# PY32F002Bxx register map
Vendor: Puya; Series: PY32F0; File version: 1.0.0
CPU: CM0+ r0p1, little endian, no MPU, no FPU, 4 interrupt priority bits
Registers are 32-bit, read-write, reset 0x0 unless marked. A register's access mark holds for its fields unless they carry their own. Offsets are from the block's base; [hi:lo] are bit positions; 'fields as' and 'values as' point back to an identical list.

## RCC — Reset and clock control
Base 0x40021000
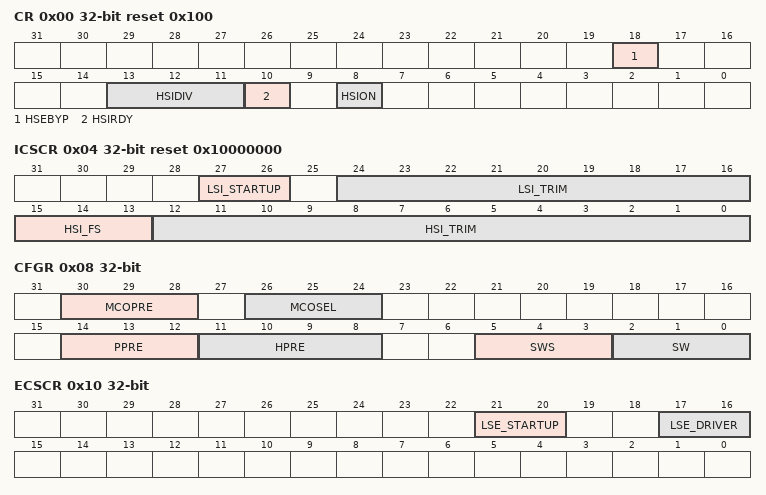
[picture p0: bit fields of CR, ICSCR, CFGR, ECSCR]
0x00 CR reset 0x100 — Clock control register
  [18] HSEBYP
    0=NotBypassed (HSE oscillator not bypassed); 1=Bypassed (HSE oscillator bypassed)
  [13:11] HSIDIV — HSI16 clock division factor
    0=NotDivided (no HSI division requested); 1=Div2 (HSI division by 2 requested); 2=Div4 (HSI division by 4 requested); 3=Div8 (HSI division by 8 requested); 4=Div16 (HSI division by 16 requested); 5=Div32 (HSI division by 32 requested); 6=Div64 (HSI division by 64 requested); 7=Div128 (HSI division by 128 requested)
  [10] HSIRDY — HSI16 clock ready flag
    on read: 0=NotReady (Oscillator is not stable); 1=Ready (Oscillator is stable)
  [8] HSION — HSI16 clock enable
0x04 ICSCR reset 0x10000000 — Internal clock sources calibration register
  [27:26] LSI_STARTUP — LSI startup time
    0=Cycles4 (4 LSI cycles for startup); 1=Cycles16 (16 LSI cycles for startup); 2=Cycles64 (64 LSI cycles for startup); 3=Cycles256 (256 LSI cycles for startup)
  [24:16] LSI_TRIM range 0..255 — LSI clock trimming
  [15:13] HSI_FS — HSI frequency selection
    0=Freq4MHz (Select internal 4 MHz oscilator); 1=Freq8MHz (Select internal 8 MHz oscilator); 2=Freq16MHz (Select internal 16 MHz oscilator); 3=Freq22_12MHz (Select internal 22.12 MHz oscilator); 4=Freq24MHz (Select internal 24 MHz oscilator)
  [12:0] HSI_TRIM range 0..31 — HSI clock trimming
0x08 CFGR — Clock configuration register
  [30:28] MCOPRE — Microcontroller clock output prescaler
    0=NotDivided (No division); 1=Div2 (Division by 2); 2=Div4 (Division by 4); 3=Div8 (Division by 8); 4=Div16 (Division by 16); 5=Div32 (Division by 32); 6=Div64 (Division by 64); 7=Div128 (Division by 128)
  [26:24] MCOSEL — Microcontroller clock output
    0=NoClock; 1=SYSCLK (SYSCLK clock selected); 3=HSI (MSI oscillator clock selected); 4=HSE (HSE oscillator clock selected); 5=PLL (PLL clock selected); 6=LSI (LSI oscillator clock selected)
  [14:12] PPRE — APB prescaler
    3=NotDivided (HCLK not divided); 4=Div2 (HCLK divided by 2); 5=Div4 (HCLK divided by 4); 6=Div8 (HCLK divided by 8); 7=Div16 (HCLK divided by 16)
  [11:8] HPRE — AHB prescaler
    7=NotDivided (system clock not divided); 8=Div2 (system clock divided by 2); 9=Div4 (system clock divided by 4); 10=Div8 (system clock divided by 8); 11=Div16 (system clock divided by 16); 12=Div64 (system clock divided by 64); 13=Div128 (system clock divided by 128); 14=Div256 (system clock divided by 256); 15=Div512 (system clock divided by 512)
  [5:3] SWS ro — System clock switch status
    0=HSISYS (HSI oscillator used as system clock); 1=HSE (HSE oscillator used as system clock); 2=PLL (PLL used as system clock); 3=LSI (LSI oscillator used as system clock)
  [2:0] SW — System clock switch
    values as SWS
0x10 ECSCR — External clock source control register
  [21:20] LSE_STARTUP
    0=Cycles4096 (4096 LSE cycles for startup); 1=Cycles2048 (2048 LSE cycles for startup); 2=Cycles8192 (8192 LSE cycles for startup); 3=Immediate (No LSE startup)
  [17:16] LSE_DRIVER
    0=Lowest driver power; 1=Low (Low driver power); 2=Default driver power; 3=Highest driver power
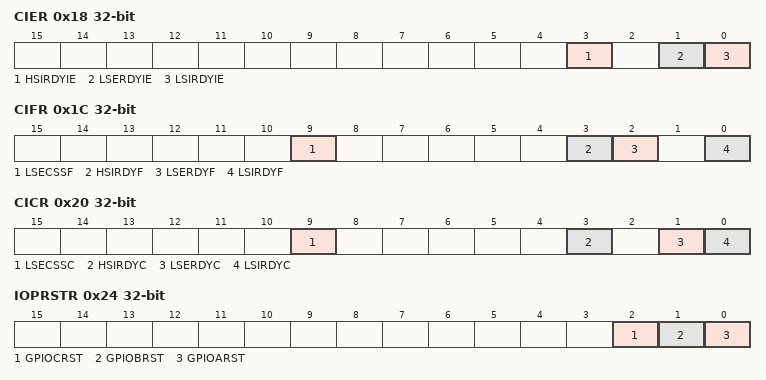
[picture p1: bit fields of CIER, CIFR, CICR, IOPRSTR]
0x18 CIER — Clock interrupt enable register
  [all] fields
    0=Disabled (Ready interrupt disabled); 1=Enabled (Ready interrupt enabled)
  [3] HSIRDYIE — HSI ready interrupt enable
  [1] LSERDYIE — LSE ready interrupt enable
  [0] LSIRDYIE — LSI ready interrupt enable
0x1C CIFR ro — Clock interrupt flag register
  [9] LSECSSF — LSE clock secure system interrupt flag
    0=No clock security interrupt caused by LSE clock failure; 1=Clock security interrupt caused by LSE clock failure
  [3] HSIRDYF — HSI ready interrupt flag
    0=NotInterrupted (No clock ready interrupt); 1=Interrupted (Clock ready interrupt)
  [2] LSERDYF — LSE ready interrupt flag
    values as HSIRDYF
  [0] LSIRDYF — LSI ready interrupt flag
    values as HSIRDYF
0x20 CICR wo — Clock interrupt clear register
  [9] LSECSSC — LSE clock secure system interrupt flag clear
  [3] HSIRDYC — HSI ready interrupt clear
    1=Clear interrupt flag
  [1] LSERDYC — LSE ready interrupt clear
    1=Clear interrupt flag
  [0] LSIRDYC — LSI ready interrupt clear
    1=Clear interrupt flag
0x24 IOPRSTR — GPIO reset register
  [all] fields
    1=Reset I/O port
  [2] GPIOCRST — I/O port C reset
  [1] GPIOBRST — I/O port B reset
  [0] GPIOARST — I/O port A reset
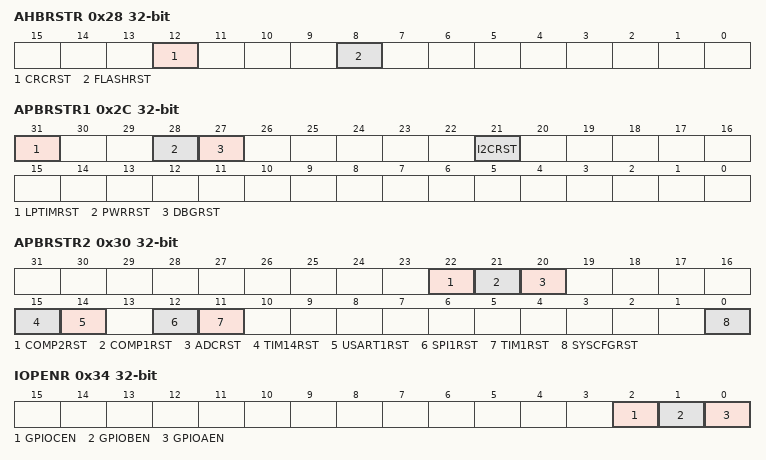
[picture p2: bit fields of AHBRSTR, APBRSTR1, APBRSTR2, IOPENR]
0x28 AHBRSTR — AHB peripheral reset register
  [12] CRCRST — CRC reset
    on write: 1=Reset the module
  [8] FLASHRST — FLASH reset
    on write: 1=Reset the module
0x2C APBRSTR1 — APB peripheral reset register 1
  [all] fields
    on write: 1=Reset the module
  [31] LPTIMRST — Low Power Timer reset
  [28] PWRRST — Power interface reset
  [27] DBGRST — Debug support reset
  [21] I2CRST — I2C reset
0x30 APBRSTR2 — APB peripheral reset register 2
  [all] fields
    on write: 1=Reset the module
  [22] COMP2RST — COMP2 reset
  [21] COMP1RST — COMP1 reset
  [20] ADCRST — ADC reset
  [15] TIM14RST — TIM14 reset
  [14] USART1RST — USART1 reset
  [12] SPI1RST — SPI1 reset
  [11] TIM1RST — TIM1 timer reset
  [0] SYSCFGRST — SYSCFG and COMP reset
0x34 IOPENR — GPIO clock enable register
  [all] fields
    0=Disabled (Port clock disabled); 1=Enabled (Port clock enabled)
  [2] GPIOCEN — I/O port C clock enable
  [1] GPIOBEN — I/O port B clock enable
  [0] GPIOAEN — I/O port A clock enable
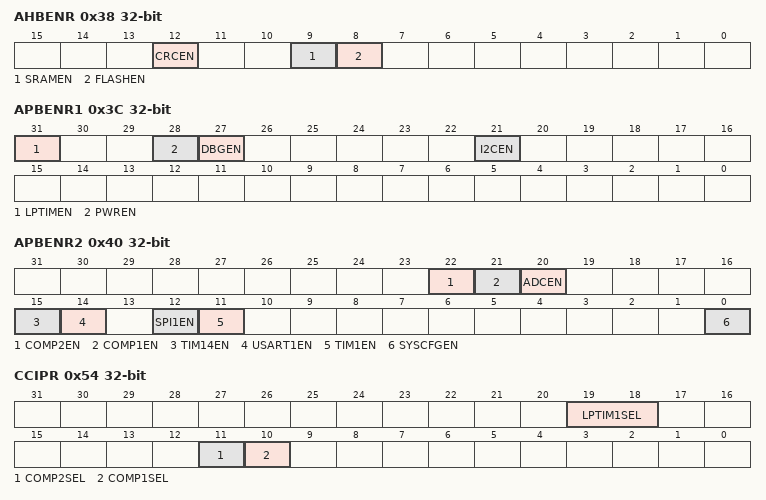
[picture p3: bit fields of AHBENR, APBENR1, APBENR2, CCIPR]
0x38 AHBENR — AHB peripheral clock enable register
  [all] fields
    0=Disabled (Clock disabled); 1=Enabled (Clock enabled)
  [12] CRCEN — CRC clock enable
  [9] SRAMEN — SRAM memory interface clock enable
  [8] FLASHEN — Flash memory interface clock enable
0x3C APBENR1 — APB peripheral clock enable register 1
  [all] fields
    0=Disabled (Clock disabled); 1=Enabled (Clock enabled)
  [31] LPTIMEN — LPTIM clock enable
  [28] PWREN — Power interface clock enable
  [27] DBGEN — Debug support clock enable
  [21] I2CEN — I2C clock enable
0x40 APBENR2 — APB peripheral clock enable register 2
  [all] fields
    0=Disabled (Clock disabled); 1=Enabled (Clock enabled)
  [22] COMP2EN — COMP2 clock enable
  [21] COMP1EN — COMP1 clock enable
  [20] ADCEN — ADC clock enable
  [15] TIM14EN — TIM14 clock enable
  [14] USART1EN — USART1 clock enable
  [12] SPI1EN — SPI1 clock enable
  [11] TIM1EN — TIM1 timer clock enable
  [0] SYSCFGEN — SYSCFG, COMP and VREFBUF clock enable
0x54 CCIPR — Peripherals independent clock configuration register
  [19:18] LPTIM1SEL — LPTIM1 clock source selection
    0=PCLK (APB clock selected as Timer clock); 1=LSI (LSI clock selected as Timer clock)
  [11] COMP2SEL — COMP2 clock source selection
    0=PCLK (APB clock selected as Timer clock); 1=LSC (LSC clock selected as Timer clock)
  [10] COMP1SEL — COMP1 clock source selection
    values as COMP2SEL
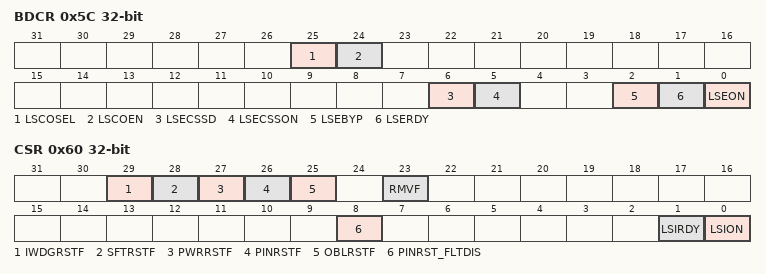
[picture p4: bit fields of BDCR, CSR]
0x5C BDCR — RTC domain control register
  [25] LSCOSEL — Low-speed clock output selection
  [24] LSCOEN — Low-speed clock output (LSCO) enable
    0=Disabled (LSCO disabled); 1=Enabled (LSCO enabled)
  [6] LSECSSD — LSE CSS detect
  [5] LSECSSON — LSE CSS enable
  [2] LSEBYP — LSE oscillator bypass
  [1] LSERDY — LSE oscillator ready
  [0] LSEON — LSE oscillator enable
0x60 CSR — Control/status register
  [29] IWDGRSTF — Independent window watchdog reset flag
    on read: 0=No reset has occured; 1=Reset (A reset has occured)
  [28] SFTRSTF — Software reset flag
    values as IWDGRSTF
  [27] PWRRSTF — BOR or POR/PDR flag
    values as IWDGRSTF
  [26] PINRSTF — Pin reset flag
    values as IWDGRSTF
  [25] OBLRSTF — Option byte loader reset flag
    values as IWDGRSTF
  [23] RMVF — Remove reset flags
    on write: 1=Clears the reset flag
  [8] PINRST_FLTDIS
  [1] LSIRDY — LSI oscillator ready
    0=NotReady (Oscillator not ready); 1=Ready (Oscillator ready)
  [0] LSION — LSI oscillator enable
    0=Off (Oscillator OFF); 1=On (Oscillator ON)
